# XMC4300 register map
Vendor: Infineon; File version: 1.0.4 (Reference Manual v1.0)
CPU: CM4 r2p0, little endian, MPU, FPU, 6 interrupt priority bits
Registers are 32-bit, read-write, reset 0x0 unless marked. A register's access mark holds for its fields unless they carry their own. Offsets are from the block's base; [hi:lo] are bit positions; {n}, {i} and the like mark numbered series.

## PORT14
Base 0x48028E00
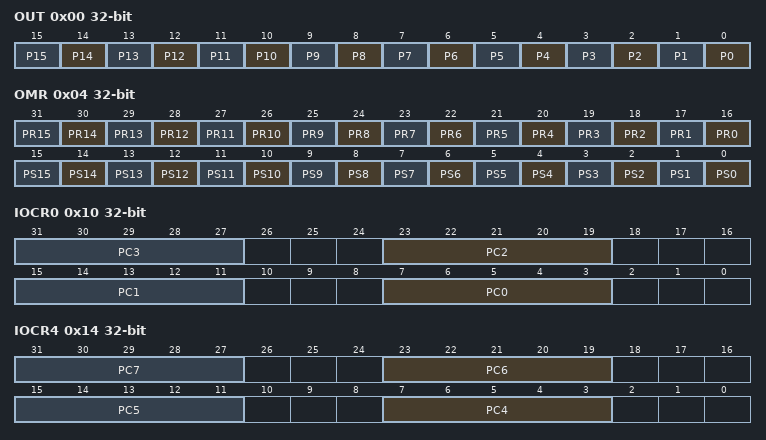
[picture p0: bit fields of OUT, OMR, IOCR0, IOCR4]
0x00 OUT — Port 14 Output Register
  [all] fields
    0=Const_0 (The output level of Pn.x is 0.); 1=Const_1 (The output level of Pn.x is 1.)
  [n] P{n} read-modifies (n=0..15) — Port n Output Bit {n}
0x04 OMR wo — Port 14 Output Modification Register
  [n+16] PR{n} (n=0..15) — Port n Reset Bit {n}
  [n] PS{n} (n=0..15) — Port n Set Bit {n}
0x10 IOCR0 — Port 14 Input/Output Control Register 0
  [8n+7:8n+3] PC{n} (n=0..3) — Port Control for Port n Pin 0 to 3
0x14 IOCR4 — Port 14 Input/Output Control Register 4
  [8n-25:8n-29] PC{n} (n=4..7) — Port Control for Port n Pin 4 to 7
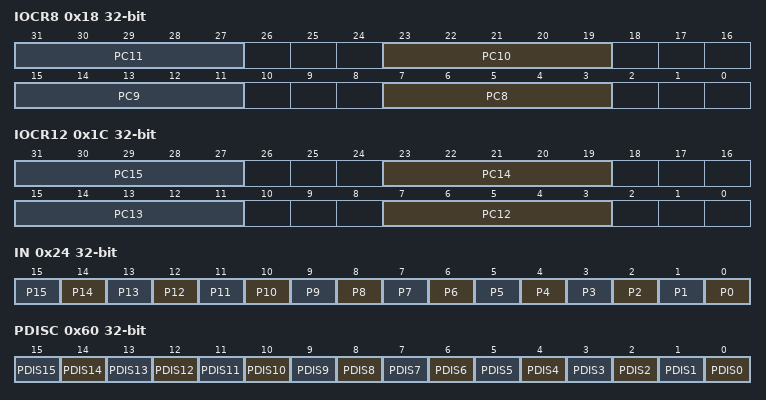
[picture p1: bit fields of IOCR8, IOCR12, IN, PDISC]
0x18 IOCR8 — Port 14 Input/Output Control Register 8
  [8n-57:8n-61] PC{n} (n=8..11) — Port Control for Port n Pin 8 to 11
0x1C IOCR12 — Port 14 Input/Output Control Register 12
  [8n-89:8n-93] PC{n} (n=12..15) — Port Control for Port n Pin 12 to 15
0x24 IN ro (reset mask 0xFFFF0000) — Port 14 Input Register
  [all] fields
    0=Const_0 (The input level of Pn.x is 0.); 1=Const_1 (The input level of Pn.x is 1.)
  [n] P{n} read-modifies (n=0..15) — Port n Input Bit {n}
0x60 PDISC (reset mask 0xFFFF0000) — Port 14 Pin Function Decision Control Register
  [all] fields
    0=Const_0 (Digital Pad input is enabled. Analog and digital input path active.); 1=Const_1 (Digital Pad input is disabled. Analog input path active. (default))
  [n] PDIS{n} (n=0..15) — Pad Disable for Port n Pin {n}
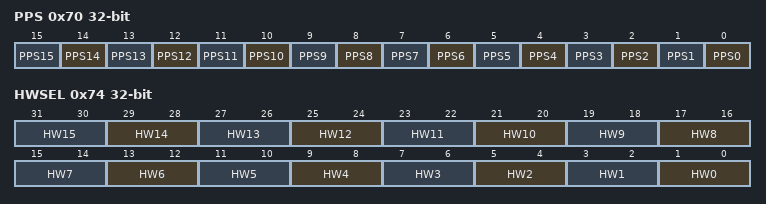
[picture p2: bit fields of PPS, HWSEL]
0x70 PPS — Port 14 Pin Power Save Register
  [all] fields
    0=Const_0 (Pin Power Save of Pn.x is disabled.); 1=Const_1 (Pin Power Save of Pn.x is enabled.)
  [n] PPS{n} (n=0..15) — Port n Pin Power Save Bit {n}
0x74 HWSEL — Port 14 Pin Hardware Select Register
  [all] fields
    0=Const_00 (Software control only.); 1=Const_01 (HWI0/HWO0 control path can override the software configuration.); 2=Const_10 (HWI1/HWO1 control path can override the software configuration.)
  [2n+1:2n] HW{n} (n=0..15) — Port n Pin Hardware Select Bit {n}

## PORT15
Base 0x48028F00
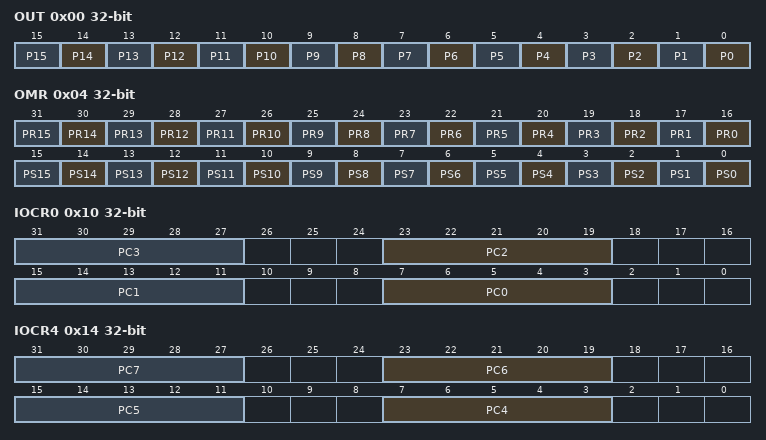
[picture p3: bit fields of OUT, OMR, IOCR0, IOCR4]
0x00 OUT — Port 15 Output Register
  [all] fields
    0=Const_0 (The output level of Pn.x is 0.); 1=Const_1 (The output level of Pn.x is 1.)
  [n] P{n} read-modifies (n=0..15) — Port n Output Bit {n}
0x04 OMR wo — Port 15 Output Modification Register
  [n+16] PR{n} (n=0..15) — Port n Reset Bit {n}
  [n] PS{n} (n=0..15) — Port n Set Bit {n}
0x10 IOCR0 — Port 15 Input/Output Control Register 0
  [8n+7:8n+3] PC{n} (n=0..3) — Port Control for Port n Pin 0 to 3
0x14 IOCR4 — Port 15 Input/Output Control Register 4
  [8n-25:8n-29] PC{n} (n=4..7) — Port Control for Port n Pin 4 to 7
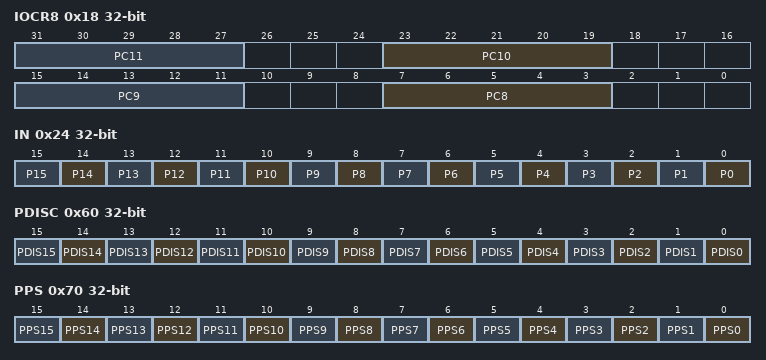
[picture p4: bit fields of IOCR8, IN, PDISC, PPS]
0x18 IOCR8 — Port 15 Input/Output Control Register 8
  [8n-57:8n-61] PC{n} (n=8..11) — Port Control for Port n Pin 8 to 11
0x24 IN ro (reset mask 0xFFFF0000) — Port 15 Input Register
  [all] fields
    0=Const_0 (The input level of Pn.x is 0.); 1=Const_1 (The input level of Pn.x is 1.)
  [n] P{n} read-modifies (n=0..15) — Port n Input Bit {n}
0x60 PDISC (reset mask 0xFFFF0000) — Port 15 Pin Function Decision Control Register
  [all] fields
    0=Const_0 (Digital Pad input is enabled. Analog and digital input path active.); 1=Const_1 (Digital Pad input is disabled. Analog input path active. (default))
  [n] PDIS{n} (n=0..15) — Pad Disable for Port n Pin {n}
0x70 PPS — Port 15 Pin Power Save Register
  [all] fields
    0=Const_0 (Pin Power Save of Pn.x is disabled.); 1=Const_1 (Pin Power Save of Pn.x is enabled.)
  [n] PPS{n} (n=0..15) — Port n Pin Power Save Bit {n}
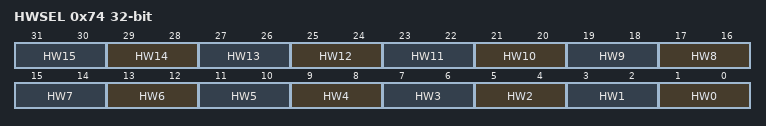
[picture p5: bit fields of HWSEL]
0x74 HWSEL — Port 15 Pin Hardware Select Register
  [all] fields
    0=Const_00 (Software control only.); 1=Const_01 (HWI0/HWO0 control path can override the software configuration.); 2=Const_10 (HWI1/HWO1 control path can override the software configuration.)
  [2n+1:2n] HW{n} (n=0..15) — Port n Pin Hardware Select Bit {n}
